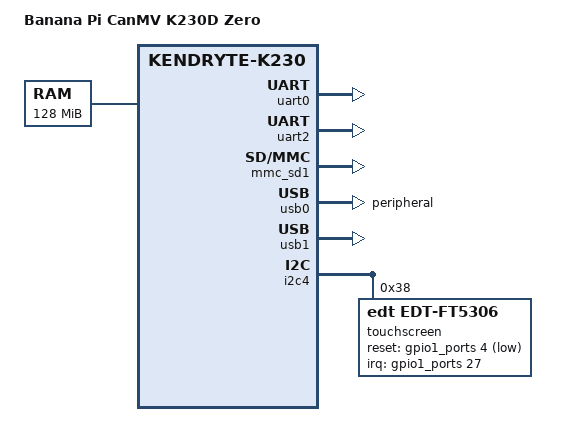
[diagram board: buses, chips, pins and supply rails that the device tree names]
// SPDX-License-Identifier: GPL-2.0 OR MIT
/*
 * Banana Pi CanMV K230D Zero: the in-tree device tree of ruyisdk's linux-xuantie-kernel at
 * ae4a7e6518cd46407be9b648828b6f704d7dc302 (arch/riscv/boot/dts/canaan/bananapi-canmv-k230d-zero.dts),
 * copied with ONE change: usb0 is in device mode (dr_mode = "peripheral"). The Gaia build it came
 * from (3d1f249, examples/boards/k230d-zero/assets/post-image.sh) made that change to the dtb with
 * sed; here it is a source change. Why: the board's USB-C port is its only network (the bring-up's
 * NCM gadget), and the in-tree tree leaves the role to the ID pin, which is not wired.
 * Copyright (C) 2024 Yangyu Chen. Untested on board.
 */

#include "k230.dtsi"
#include "display-st7701-480x800.dtsi"

/ {
	model = "Banana Pi CanMV K230D Zero";
	compatible = "canaan,canmv-k230", "canaan,kendryte-k230";

	aliases {
		serial2 = &uart2;
	};

	chosen {
		stdout-path = "serial0:115200n8";
		bootargs = "root=/dev/mmcblk0p2 loglevel=8 rw rootdelay=4 \
						rootfstype=ext4 console=ttyS0,115200  earlycon=sbi";
	};

	ddr: memory@0 {
		device_type = "memory";
		reg = <0x0 0x0 0x0 0x8000000>;
	};

	sound {
		status                      = "okay";
		compatible                  = "canaan,k230-audio-inno";
		canaan,model                = "K230_I2S_INNO";
		canaan,k230-i2s-controller  = <&i2s>;
		canaan,k230-audio-codec     = <&inno_codec>;
	};
};

&uart0 {
	status = "okay";
};
&uart2 {
	status = "okay";
};
&mmc_sd1{
	status = "okay";
	no-1-8-v;
	cap-sd-highspeed;
	mshc_ctrl_r = <0x00>;
};
&usb0 {
	status = "okay";
	dr_mode = "peripheral";
};
&usb1 {
	status = "okay";
};

&i2c4 {
	status = "okay";
	touchscreen@38 {
		compatible = "edt,edt-ft5306";
		reg = <0x38>;
		reset-gpios = <&gpio1_ports 4 GPIO_ACTIVE_LOW>;
		interrupt-parent = <&gpio1_ports>;
		interrupts = <27 IRQ_TYPE_EDGE_FALLING>;
	};
};

&lcd {
	dsi_reset-gpios = <&gpio1_ports 5 GPIO_ACTIVE_HIGH>;
};

&mipi0 {
	// set to csi2
	id = <2>;
	reg = <0x0 0x9000a800 0x0 0x800>;
	interrupts = <121 IRQ_TYPE_LEVEL_HIGH>;
	resets = <&sysctl_reset
			  K230_RESET_CSI2_REG_OFFSET
			  K230_RESET_CSI2_TYPE
			  K230_RESET_CSI2_DONE_BIT
			  K230_RESET_CSI2_ASSERT_BIT>,
			 <&sysctl_reset
			  K230_RESET_M2_REG_OFFSET
			  K230_RESET_M2_TYPE
			  K230_RESET_M2_DONE_BIT
			  K230_RESET_M2_ASSERT_BIT>;
};
